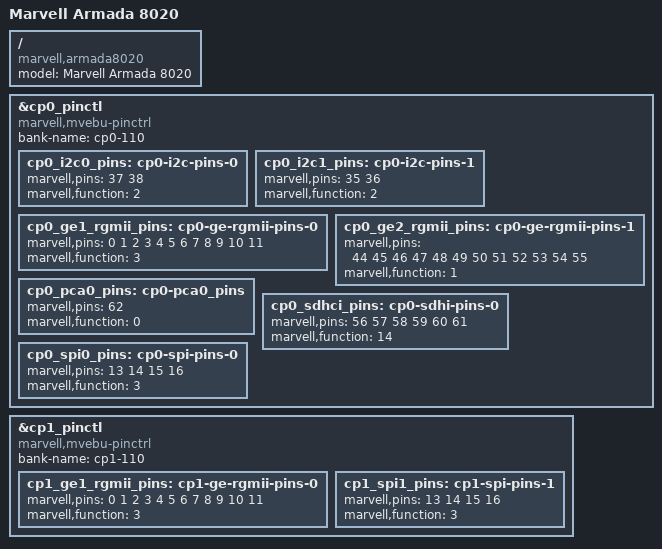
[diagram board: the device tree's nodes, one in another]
/*
 * Copyright (C) 2016 Marvell Technology Group Ltd.
 *
 * This file is dual-licensed: you can use it either under the terms
 * of the GPLv2 or the X11 license, at your option. Note that this dual
 * licensing only applies to this file, and not this project as a
 * whole.
 *
 *  a) This library is free software; you can redistribute it and/or
 *     modify it under the terms of the GNU General Public License as
 *     published by the Free Software Foundation; either version 2 of the
 *     License, or (at your option) any later version.
 *
 *     This library is distributed in the hope that it will be useful,
 *     but WITHOUT ANY WARRANTY; without even the implied warranty of
 *     MERCHANTABILITY or FITNESS FOR A PARTICULAR PURPOSE.  See the
 *     GNU General Public License for more details.
 *
 * Or, alternatively,
 *
 *  b) Permission is hereby granted, free of charge, to any person
 *     obtaining a copy of this software and associated documentation
 *     files (the "Software"), to deal in the Software without
 *     restriction, including without limitation the rights to use,
 *     copy, modify, merge, publish, distribute, sublicense, and/or
 *     sell copies of the Software, and to permit persons to whom the
 *     Software is furnished to do so, subject to the following
 *     conditions:
 *
 *     The above copyright notice and this permission notice shall be
 *     included in all copies or substantial portions of the Software.
 *
 *     THE SOFTWARE IS PROVIDED "AS IS", WITHOUT WARRANTY OF ANY KIND,
 *     EXPRESS OR IMPLIED, INCLUDING BUT NOT LIMITED TO THE WARRANTIES
 *     OF MERCHANTABILITY, FITNESS FOR A PARTICULAR PURPOSE AND
 *     NONINFRINGEMENT. IN NO EVENT SHALL THE AUTHORS OR COPYRIGHT
 *     HOLDERS BE LIABLE FOR ANY CLAIM, DAMAGES OR OTHER LIABILITY,
 *     WHETHER IN AN ACTION OF CONTRACT, TORT OR OTHERWISE, ARISING
 *     FROM, OUT OF OR IN CONNECTION WITH THE SOFTWARE OR THE USE OR
 *     OTHER DEALINGS IN THE SOFTWARE.
 */

/*
 * Device Tree file for the Armada 8020 SoC, made of an AP806 Dual and
 * two CP110.
 */

#include <dt-bindings/gpio/gpio.h>
#include "armada-common.dtsi"
#include "armada-ap806-dual.dtsi"

#define CP110_NAME		cp0
#define CP110_BASE              0xf2000000
#define CP110_PCIE_MEM_BASE     0xf6000000
#define CP110_PCIE_MEM_OFFSET	0x1000000

#include "armada-cp110.dtsi"

#undef CP110_NAME
#undef CP110_BASE
#undef CP110_PCIE_MEM_BASE

#define CP110_NAME		cp1
#define CP110_BASE              0xf4000000
#define CP110_PCIE_MEM_BASE     0xfa000000

#include "armada-cp110.dtsi"

#undef CP110_NAME
#undef CP110_BASE
#undef CP110_PCIE_MEM_BASE

/ {
	model = "Marvell Armada 8020";
	compatible = "marvell,armada8020", "marvell,armada-ap806-dual",
		     "marvell,armada-ap806";
};

&cp0_pinctl {
	compatible = "marvell,mvebu-pinctrl", "marvell,armada-8k-cpm-pinctrl";
	bank-name ="cp0-110";

	cp0_i2c0_pins: cp0-i2c-pins-0 {
		marvell,pins = < 37 38 >;
		marvell,function = <2>;
	};
	cp0_i2c1_pins: cp0-i2c-pins-1 {
		marvell,pins = < 35 36 >;
		marvell,function = <2>;
	};
	cp0_ge1_rgmii_pins: cp0-ge-rgmii-pins-0 {
		marvell,pins = < 0 1 2 3 4 5 6 7 8 9 10 11>;
		marvell,function = <3>;
	};
	cp0_ge2_rgmii_pins: cp0-ge-rgmii-pins-1 {
		marvell,pins = < 44 45 46 47 48 49 50 51
				52 53 54 55 >;
		marvell,function = <1>;
	};
	cp0_pca0_pins: cp0-pca0_pins {
		marvell,pins = <62>;
		marvell,function = <0>;
	};
	cp0_sdhci_pins: cp0-sdhi-pins-0 {
		marvell,pins = < 56 57 58 59 60 61 >;
		marvell,function = <14>;
	};
	cp0_spi0_pins: cp0-spi-pins-0 {
		marvell,pins = < 13 14 15 16 >;
		marvell,function = <3>;
	};
};

&cp1_pinctl {
	compatible = "marvell,mvebu-pinctrl", "marvell,armada-8k-cps-pinctrl";
	bank-name ="cp1-110";

	cp1_ge1_rgmii_pins: cp1-ge-rgmii-pins-0 {
		marvell,pins = < 0 1 2 3 4 5 6 7 8 9 10 11 >;
		marvell,function = <3>;
	};
	cp1_spi1_pins: cp1-spi-pins-1 {
		marvell,pins = < 13 14 15 16 >;
		marvell,function = <3>;
	};
};
